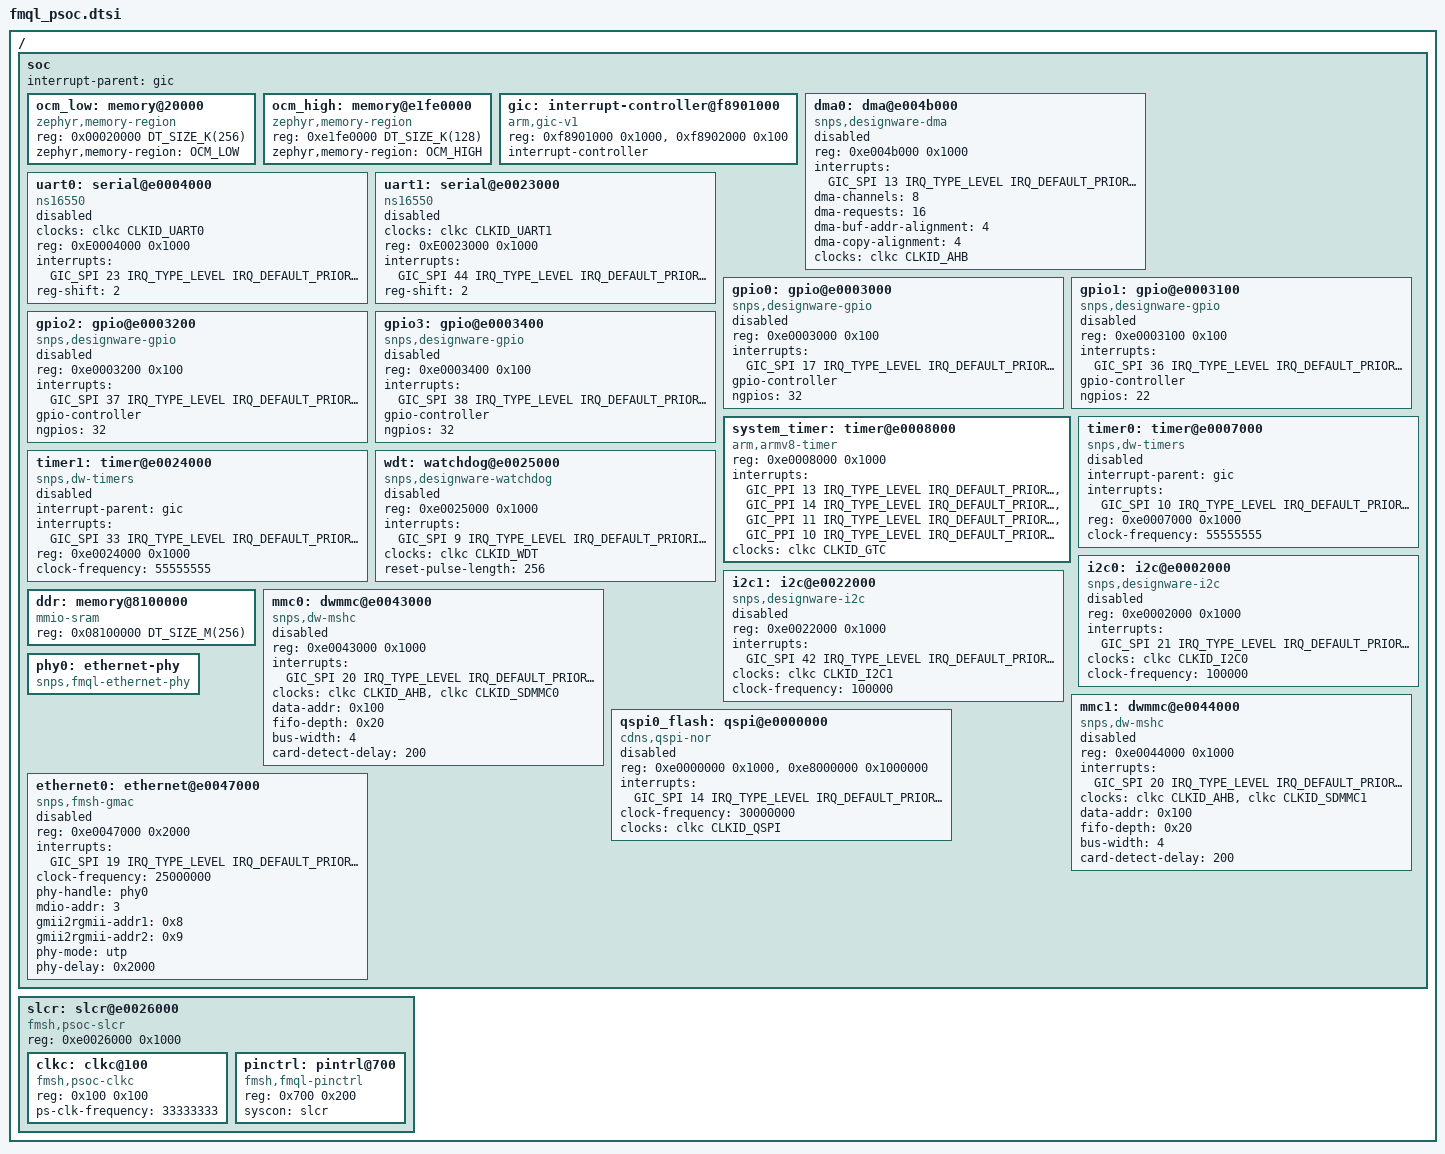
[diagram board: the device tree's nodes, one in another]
/*
 * Copyright (c) 2024 SYSTech Co.
 * SPDX-License-Identifier: Apache-2.0
 */

#include <mem.h>
#include <freq.h>
#include <arm/armv7-a.dtsi>
#include <zephyr/dt-bindings/interrupt-controller/arm-gic.h>
#include <zephyr/dt-bindings/clock/fmsh_psoc_clock.h>
#include <zephyr/dt-bindings/i2c/i2c.h>

/ {

	soc {
		interrupt-parent = <&gic>;

		ocm_low: memory@20000 {
			compatible = "zephyr,memory-region", "xlnx,zynq-ocm";
			reg = <0x00020000 DT_SIZE_K(256)>;
			zephyr,memory-region = "OCM_LOW";
		};

		ocm_high: memory@e1fe0000{
			compatible = "zephyr,memory-region", "xlnx,zynq-ocm";
			reg = <0xe1fe0000 DT_SIZE_K(128)>;
			zephyr,memory-region = "OCM_HIGH";
		};

		gic: interrupt-controller@f8901000 {
			compatible = "arm,gic-v1", "arm,gic";
			status = "okay";
			reg = <0xf8901000 0x1000>,
				<0xf8902000 0x100>;
			interrupt-controller;
			#interrupt-cells = <4>;
		};

		dma0: dma@e004b000 {
			compatible = "snps,designware-dma";
			reg = <0xe004b000 0x1000>;
			interrupts = <GIC_SPI 13 IRQ_TYPE_LEVEL IRQ_DEFAULT_PRIORITY>;
			interrupt-names = "irq_0";
			#dma-cells = <1>;
			dma-channels = <8>;
			dma-requests = <16>;
			dma-buf-addr-alignment = <4>;
			dma-copy-alignment = <4>;
			clocks = <&clkc CLKID_AHB>;
			clock-names = "hclk";
			status = "disabled";
		};

		uart0: serial@e0004000 {
			compatible = "ns16550";
			clocks = <&clkc CLKID_UART0>;
			clock-names = "uart0";
			reg = <0xE0004000 0x1000>;
			interrupts = <GIC_SPI 23 IRQ_TYPE_LEVEL IRQ_DEFAULT_PRIORITY>;
			interrupt-names = "irq_0";
			reg-shift = <2>;
			// reg-io-width = <4>;
			// u-boot,dm-pre-reloc;
			status = "disabled";
		};

		uart1: serial@e0023000 {
			compatible = "ns16550";
			clocks = <&clkc CLKID_UART1>;
			clock-names = "uart1";
			reg = <0xE0023000 0x1000>;
			interrupts = <GIC_SPI 44 IRQ_TYPE_LEVEL IRQ_DEFAULT_PRIORITY>;
			interrupt-names = "irq_0";
			reg-shift = <2>;
			// reg-io-width = <4>;
			// u-boot,dm-pre-reloc;
			status = "disabled";
		};

		gpio0: gpio@e0003000 {
			#address-cells = <1>;
			#size-cells = <0>;
			compatible = "snps,designware-gpio";
			reg = <0xe0003000 0x100>;
			interrupts = <GIC_SPI 17 IRQ_TYPE_LEVEL IRQ_DEFAULT_PRIORITY>;
			gpio-controller;
			ngpios = <32>;
			#gpio-cells = <2>;
			status = "disabled";
		};

		gpio1: gpio@e0003100 {
			#address-cells = <1>;
			#size-cells = <0>;
			compatible = "snps,designware-gpio";
			reg = <0xe0003100 0x100>;
			interrupts = <GIC_SPI 36 IRQ_TYPE_LEVEL IRQ_DEFAULT_PRIORITY>;
			gpio-controller;
			ngpios = <22>;
			#gpio-cells = <2>;
			status = "disabled";
		};

		gpio2: gpio@e0003200 {
			#address-cells = <1>;
			#size-cells = <0>;
			compatible = "snps,designware-gpio";
			reg = <0xe0003200 0x100>;
			interrupts = <GIC_SPI 37 IRQ_TYPE_LEVEL IRQ_DEFAULT_PRIORITY>;
			gpio-controller;
			ngpios = <32>;
			#gpio-cells = <2>;
			status = "disabled";
		};

		gpio3: gpio@e0003400 {
			#address-cells = <1>;
			#size-cells = <0>;
			compatible = "snps,designware-gpio";
			reg = <0xe0003400 0x100>;
			interrupts = <GIC_SPI 38 IRQ_TYPE_LEVEL IRQ_DEFAULT_PRIORITY>;
			gpio-controller;
			ngpios = <32>;
			#gpio-cells = <2>;
			status = "disabled";
		};


		system_timer: timer@e0008000 {
			compatible = "arm,armv8-timer";
			reg = <0xe0008000 0x1000>;
			interrupts =
				<GIC_PPI 13 IRQ_TYPE_LEVEL IRQ_DEFAULT_PRIORITY>,
				<GIC_PPI 14 IRQ_TYPE_LEVEL IRQ_DEFAULT_PRIORITY>,
				<GIC_PPI 11 IRQ_TYPE_LEVEL IRQ_DEFAULT_PRIORITY>,
				<GIC_PPI 10 IRQ_TYPE_LEVEL IRQ_DEFAULT_PRIORITY>;
			interrupt-names =
				"secure_timer",
				"non-sec_timer",
				"virt_timer",
				"hyp_timer";
			clocks = <&clkc CLKID_GTC>;
			clock-names = "gtc";
		};

		timer0: timer@e0007000 {
			compatible = "snps,dw-timers";
			interrupt-parent = <&gic>;
			interrupts = <GIC_SPI 10 IRQ_TYPE_LEVEL IRQ_DEFAULT_PRIORITY>;
			reg = <0xe0007000 0x1000>;
			clock-frequency = < 55555555 >;
			status = "disabled";
		};

		timer1: timer@e0024000 {
			compatible = "snps,dw-timers";
			interrupt-parent = <&gic>;
			interrupts = <GIC_SPI 33 IRQ_TYPE_LEVEL IRQ_DEFAULT_PRIORITY>;
			reg = <0xe0024000 0x1000>;
			clock-frequency = < 55555555 >;
			status = "disabled";
		};

		wdt: watchdog@e0025000 {
			compatible = "snps,designware-watchdog";
			reg = <0xe0025000 0x1000>;
			interrupts = <GIC_SPI 9 IRQ_TYPE_LEVEL IRQ_DEFAULT_PRIORITY>;
			interrupt-names = "irq_0";
			clocks = <&clkc CLKID_WDT>;
			clock-names = "iwdt";
			reset-pulse-length = <256>; // 256 pclk cycles
			status = "disabled";
		};

		i2c0: i2c@e0002000 {
			compatible = "snps,designware-i2c";
			reg = <0xe0002000 0x1000>;
			interrupts = <GIC_SPI 21 IRQ_TYPE_LEVEL IRQ_DEFAULT_PRIORITY>;
			clocks = <&clkc CLKID_I2C0>;
			clock-names = "i2c";
			clock-frequency = <100000>; // 100kHz
			#address-cells = <1>;
			#size-cells = <0>;
			status = "disabled";
		};

		i2c1: i2c@e0022000 {
			compatible = "snps,designware-i2c";
			reg = <0xe0022000 0x1000>;
			interrupts = <GIC_SPI 42 IRQ_TYPE_LEVEL IRQ_DEFAULT_PRIORITY>;
			clocks = <&clkc CLKID_I2C1>;
			clock-names = "i2c";
			clock-frequency = <100000>; // 100kHz
			#address-cells = <1>;
			#size-cells = <0>;
			status = "disabled";
		};

		ddr: memory@8100000 {
			compatible = "mmio-sram";
			reg = <0x08100000 DT_SIZE_M(256)>;
		};

		mmc0: dwmmc@e0043000 {
			compatible = "snps,dw-mshc";
			reg = <0xe0043000 0x1000>;
			interrupts = <GIC_SPI 20 IRQ_TYPE_LEVEL IRQ_DEFAULT_PRIORITY>;
			clocks = <&clkc CLKID_AHB>, <&clkc CLKID_SDMMC0>;
			clock-names = "biu", "ciu";
			#address-cells = <1>;
			#size-cells = <0>;
			data-addr = <0x100>;
			fifo-depth = <0x20>;
			bus-width = <4>;
			status = "disabled";

			/* device */
			card-detect-delay = <200>;

			/* enable dma */
			// dmas = <&dmahost 0 0 0>;
			// dma-names = "rx-tx";
		};
		mmc1: dwmmc@e0044000 {
			compatible = "snps,dw-mshc";
			reg = <0xe0044000 0x1000>;
			interrupts = <GIC_SPI 20 IRQ_TYPE_LEVEL IRQ_DEFAULT_PRIORITY>;
			clocks = <&clkc CLKID_AHB>, <&clkc CLKID_SDMMC1>;
			clock-names = "biu", "ciu";
			#address-cells = <1>;
			#size-cells = <0>;
			data-addr = <0x100>;
			fifo-depth = <0x20>;
			bus-width = <4>;
			status = "disabled";

			/* device */
			card-detect-delay = <200>;

			/* mmc1 not support dma */
		};

		qspi0_flash: qspi@e0000000 {
			compatible = "cdns,qspi-nor";
			reg = <0xe0000000 0x1000>,
				<0xe8000000 0x1000000>;
			reg-names = "qspi_reg", "qspi_data";
			interrupts = <GIC_SPI 14 IRQ_TYPE_LEVEL IRQ_DEFAULT_PRIORITY>;
			interrupt-names = "irq_0";
			clock-frequency = <30000000>;
			clocks = <&clkc CLKID_QSPI>;
			clock-names = "qspi";
			status = "disabled";
		};

		phy0: ethernet-phy {
			compatible = "snps,fmql-ethernet-phy";
			status = "okay";
		};

		ethernet0: ethernet@e0047000 {
			compatible = "snps,fmsh-gmac";
			reg = <0xe0047000 0x2000>;
			interrupts = <GIC_SPI 19 IRQ_TYPE_LEVEL IRQ_DEFAULT_PRIORITY>;
			interrupt-names = "irq_0";
			clock-frequency = <25000000>;
			phy-handle = <&phy0>;
			mdio-addr = <3>;
			gmii2rgmii-addr1 = <0x8>;
			gmii2rgmii-addr2 = <0x9>;
			phy-mode = "utp";  /* fiber or utp */
			phy-delay = <0x2000>;
			status = "disabled";
		};
	};

	slcr: slcr@e0026000 {
		#address-cells = <1>;
		#size-cells = <1>;
		compatible = "fmsh,psoc-slcr", "syscon";
		reg = <0xe0026000 0x1000>;

		ranges;

		clkc: clkc@100 {
			compatible = "fmsh,psoc-clkc";
			reg = <0x100 0x100>;
			#clock-cells = <1>;
			ps-clk-frequency = <33333333>;
			status = "okay";
		};

		pinctrl: pintrl@700 {
			compatible = "fmsh,fmql-pinctrl";
			reg = <0x700 0x200>;
			syscon = <&slcr>;
		};
	};
};
